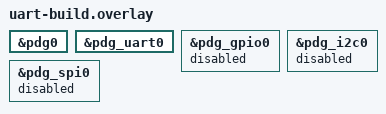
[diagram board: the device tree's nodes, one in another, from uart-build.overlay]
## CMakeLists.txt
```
# Copyright (c) 2026 Open Device Partnership and Contributors
# SPDX-License-Identifier: MIT

cmake_minimum_required(VERSION 3.20.0)

set(BOARD native_sim/native/64 CACHE STRING "Default board for Pico de Gallo M5 tests")
set(SHIELD pico_de_gallo CACHE STRING "Default shield for Pico de Gallo M5 tests")
get_filename_component(PDG_MODULE_ROOT "${CMAKE_CURRENT_LIST_DIR}/../../../.." ABSOLUTE)
list(APPEND EXTRA_ZEPHYR_MODULES "${PDG_MODULE_ROOT}")

find_package(Zephyr REQUIRED HINTS $ENV{ZEPHYR_BASE})
project(pdg_m5_reset_subscriptions)

target_sources(app PRIVATE src/main.c)

# pdg_mfd.h is the child-facing accessor for the borrowed context; m5_bottom.h
# is this suite's host-context shim interface. Both are basic-C-types headers.
target_include_directories(app PRIVATE
	${PDG_MODULE_ROOT}/zephyr/drivers/mfd
	${CMAKE_CURRENT_LIST_DIR}/../common)

# The shim runs in the native simulator (host) context, where the generated
# pico_de_gallo.h lives. Same mechanism as zephyr/drivers/CMakeLists.txt.
target_sources(native_simulator INTERFACE ${CMAKE_CURRENT_LIST_DIR}/../common/m5_bottom.c)
target_include_directories(native_simulator INTERFACE ${CMAKE_CURRENT_LIST_DIR}/../common)
```

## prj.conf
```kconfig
# Copyright (c) 2026 Open Device Partnership and Contributors
# SPDX-License-Identifier: MIT

CONFIG_LOG=y
CONFIG_LOG_MODE_IMMEDIATE=y
CONFIG_PRINTK=y

# Both children are disabled in reset.overlay, so neither subsystem is needed.
# Stated explicitly so an accidental re-enable is visible in review.
CONFIG_GPIO=n
CONFIG_SPI=n
```

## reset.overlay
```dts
/*
 * Copyright (c) 2026 Open Device Partnership and Contributors
 *
 * SPDX-License-Identifier: MIT
 *
 * M5 reset image topology: parent okay, BOTH children explicitly disabled.
 *
 * This is not decoration. Acceptance spec §3 resolves an init-order conflict:
 * the firmware may still own chip-select pin 2 through an orphaned GPIO event
 * subscription, and pdg_spi_init()'s gpio_pin_configure_dt(GPIO_OUTPUT_INACTIVE)
 * would then fail -EBUSY before main() ever gets to clear it. Disabling both
 * children means nothing touches pin 2 before the reset endpoint runs.
 *
 * The four M5 images therefore share only fixture-identity.dtsi. Do not factor
 * this topology into a common fragment.
 */

#include "../fixture-identity.dtsi"

&pdg0 {
	status = "okay";
};

&pdg_gpio0 {
	status = "disabled";
};

&pdg_spi0 {
	status = "disabled";
};
```

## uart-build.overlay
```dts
/*
 * Copyright (c) 2026 Open Device Partnership and Contributors
 *
 * SPDX-License-Identifier: MIT
 *
 * M5 UART build-gate topology: parent okay, UART okay, every other child
 * explicitly disabled.
 *
 * This overlay exists only so `pdg_uart.c` has a compiling/linking build
 * target. Spec §9: M5 defers the UART sample and the fake-based suite to M6,
 * and the shield's `pdg_uart0` is disabled by default, so without this overlay
 * no target would ever compile the driver.
 *
 * It reuses the reset_subscriptions application unchanged. That application
 * depends only on the MFD accessor and the m5_bottom reset shim, and its
 * BUILD_ASSERTs (`src/main.c:38-46`) require exactly parent okay plus
 * pdg_gpio0 and pdg_spi0 disabled -- which is what this file emits. It says
 * nothing about UART, and `prj.conf` does not disable SERIAL, so a
 * UART-enabled tree still builds. The binary is NEVER run: booting it would
 * reach gallo_init_strict() and open USB.
 *
 * I2C is disabled explicitly rather than by relying on the shield default, so
 * that ci-build.sh's negative Kconfig assertion for CONFIG_I2C_PICO_DE_GALLO
 * is unambiguous at the point of use.
 *
 * Per fixture-identity.dtsi, topology is deliberately per-image. Do not factor
 * this into a shared fragment.
 */

#include "../fixture-identity.dtsi"

&pdg0 {
	status = "okay";
};

&pdg_uart0 {
	status = "okay";
};

&pdg_gpio0 {
	status = "disabled";
};

&pdg_i2c0 {
	status = "disabled";
};

&pdg_spi0 {
	status = "disabled";
};
```

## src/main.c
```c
/*
 * Copyright (c) 2026 Open Device Partnership and Contributors
 *
 * SPDX-License-Identifier: MIT
 *
 * M5 phase 1 -- explicit firmware GPIO subscription reset.
 *
 * Acceptance spec §3. The parent's init performs the strict open; main() then
 * calls the reset endpoint exactly once. Both children are disabled in
 * reset.overlay, so nothing has touched chip-select pin 2 by the time the reset
 * runs -- which is the entire point of giving this its own image.
 *
 * "Idempotent" is conditional: reset is safe only while the firmware dispatcher
 * can service the endpoint. It cannot preempt an outstanding serial,
 * zero-timeout gpio/wait-*, which wedges dispatch device-wide. Reset affects
 * subscriptions ONLY -- not pin modes, pulls, output levels, SPI configuration,
 * or any Zephyr-side lock/latch state.
 *
 * Every failed check exits nonzero. M5_RESET_PASS is printed only after every
 * check has passed.
 */

#include <zephyr/device.h>
#include <zephyr/devicetree.h>
#include <zephyr/kernel.h>
#include <zephyr/sys/printk.h>

#include "posix_board_if.h"

#include "pdg_mfd.h"
#include "m5_bottom.h"

/*
 * Topology, asserted at build time as well as in the generated devicetree.
 * A child quietly re-enabled here would reintroduce exactly the init-order
 * conflict this image exists to avoid, and would do it silently.
 */
BUILD_ASSERT(DT_NODE_HAS_STATUS_OKAY(DT_NODELABEL(pdg0)),
	     "M5 reset image requires the odp,pico-de-gallo parent to be okay");
BUILD_ASSERT(!DT_NODE_HAS_STATUS_OKAY(DT_NODELABEL(pdg_gpio0)),
	     "M5 reset image requires pdg_gpio0 to be disabled: an enabled GPIO child "
	     "could touch chip-select pin 2 before the subscription reset runs");
BUILD_ASSERT(!DT_NODE_HAS_STATUS_OKAY(DT_NODELABEL(pdg_spi0)),
	     "M5 reset image requires pdg_spi0 to be disabled: pdg_spi_init() configures "
	     "every cs-gpios pin as an inactive output and would fail -EBUSY on a "
	     "monitored pin before the subscription reset runs");

int main(void)
{
	const struct device *const parent = DEVICE_DT_GET(DT_NODELABEL(pdg0));
	uint8_t reset_count = 0U;
	void *ctx;
	int ret;

	printk("M5_RESET_BEGIN\n");

	if (!device_is_ready(parent)) {
		printk("M5_RESET_FAIL reason=parent-not-ready device=%s\n", parent->name);
		posix_exit(1);
	}

	/*
	 * pdg_mfd.h contract: require readiness first, then borrow. A NULL
	 * context after a passing readiness check is an ownership invariant
	 * failure, not an expected case. The context is borrowed -- never close
	 * or free it.
	 */
	ctx = pdg_mfd_ctx(parent);
	if (ctx == NULL) {
		printk("M5_RESET_FAIL reason=null-context device=%s\n", parent->name);
		posix_exit(1);
	}

	ret = m5_bottom_reset_subscriptions(ctx, &reset_count);
	if (ret != 0) {
		printk("M5_RESET_FAIL reason=reset-endpoint errno=%d\n", ret);
		posix_exit(1);
	}

	/*
	 * The count is evidence, not decoration. Test design §6.4 part 3: a
	 * nonzero count after a supposedly-normal acceptance phase is direct
	 * evidence that T4's cleanup did not run. The runner carries this value
	 * into teardown.subscriptions_reset in the aggregate verdict.
	 */
	printk("M5_RESET_COUNT=%u\n", reset_count);
	printk("M5_RESET_PASS\n");

	posix_exit(0);

	return 0;
}
```
